# MCXN947_cm33_core0 register map
Vendor: nxp.com; File version: 1.0
CPU: CM33 r2p0, little endian, MPU, FPU, VTOR, 3 interrupt priority bits
Registers are 32-bit, read-write, reset 0x0 unless marked. A register's access mark holds for its fields unless they carry their own. Offsets are from the block's base; [hi:lo] are bit positions; lines under a group give offsets from that group; {n}, {i} and the like mark numbered series; 'fields as' and 'values as' point back to an identical list.

## ITRC0 — Intrusion and Tamper Response Controller
Base 0x40026000
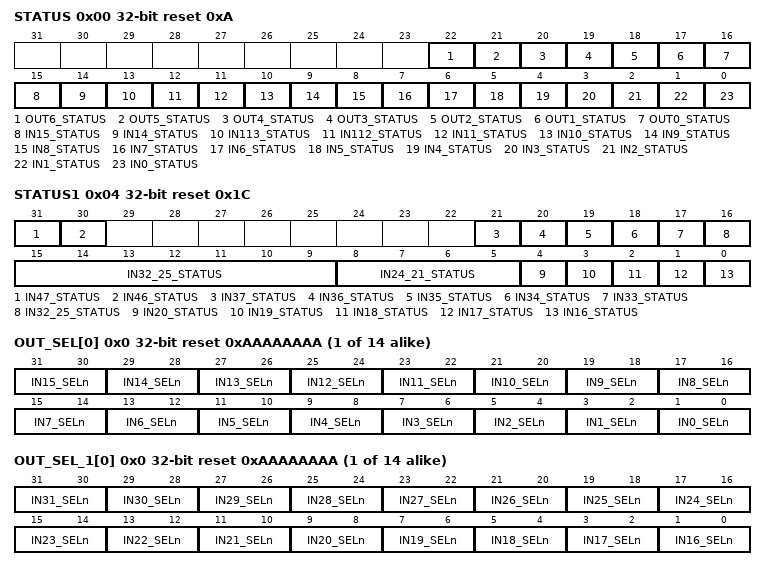
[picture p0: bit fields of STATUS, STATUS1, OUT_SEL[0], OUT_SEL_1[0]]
0x00 STATUS reset 0xA write-1-clears — ITRC outputs and IN0 to IN15 Status
  [all] fields
    0=DISABLE (Output not triggered.); 1=ENABLE (Output has been triggered.)
  [22] OUT6_STATUS write-1-clears — ITRC triggered TMPR_OUT1 internal signal connected to various on-chip multiplexers.
  [21] OUT5_STATUS write-1-clears — ITRC triggered TMPR_OUT0 internal signal connected to various on-chip multiplexers.
  [20] OUT4_STATUS write-1-clears — ITRC triggered CHIP_RESET to reset the chip after all other response process finished.
  [19] OUT3_STATUS write-1-clears — ITRC triggered RAM_ZEROIZE.
  [18] OUT2_STATUS write-1-clears — ITRC triggered PUF_ZEROIZE to clear PUF key store and RAM.
  [17] OUT1_STATUS write-1-clears — ITRC triggered ELS_RESET to clear ELS key store.
  [16] OUT0_STATUS write-1-clears — ITRC triggered ITRC_IRQ output.
  [15] IN15_STATUS write-1-clears — Software event 1 occurred.
  [14] IN14_STATUS write-1-clears — Software event 0 occurred.
  [13] IN113_STATUS write-1-clears — FREQME out of range status output.
  [12] IN112_STATUS write-1-clears — Watchdog 1 timer event interrupt.
  [11] IN11_STATUS write-1-clears — Code Watchdog 1 interrupt.
  [10] IN10_STATUS write-1-clears — PKC module detected an error event.
  [9] IN9_STATUS write-1-clears — SPC VDD_CORE glitch detect event occurred.
  [8] IN8_STATUS write-1-clears — ELS error event occurred.
  [7] IN7_STATUS write-1-clears — AHB secure bus checkers detected illegal access.
  [6] IN6_STATUS write-1-clears — Flash ECC mismatch event occurred.
  [5] IN5_STATUS write-1-clears — Watch Dog timer event occurred.
  [4] IN4_STATUS write-1-clears — SPC VDD_CORE_LVD detect.
  [3] IN3_STATUS write-1-clears — VDD_MAIN volt tamper output.
  [2] IN2_STATUS write-1-clears — Code Watchdog 0 interrupt.
  [1] IN1_STATUS write-1-clears — TDET tamper output.
  [0] IN0_STATUS write-1-clears — GDET0 & 1 interrupt.
0x04 STATUS1 reset 0x1C write-1-clears — ITRC IN16 to IN47 Status
  [all] fields
    values as the fields of STATUS
  [31] IN47_STATUS write-1-clears — TRNG HW error event occurred.
  [30] IN46_STATUS write-1-clears — SM3 SGI error event occurred.
  [21] IN37_STATUS write-1-clears — FLEXSPI GCM error event occurred.
  [20] IN36_STATUS write-1-clears — SPC VDD_IO high voltage detect event occurred.
  [19] IN35_STATUS write-1-clears — SPC VDD_SYS_HVD high voltage detect event occurred.
  [18] IN34_STATUS write-1-clears — SPC VDD_CORE high voltage detect event occurred.
  [17] IN33_STATUS write-1-clears — GDET0/1 SFR error event occurred.
  [16:9] IN32_25_STATUS write-1-clears — MSF SOCTRIM 7~0 ECC error event occurred.
  [8:5] IN24_21_STATUS write-1-clears — INTM interrupt monitor error 3~0 event occurred.
  [4] IN20_STATUS write-1-clears — VDD_MAIN clock tamper output event occurred.
  [3] IN19_STATUS write-1-clears — Reserved
  [2] IN18_STATUS write-1-clears — Reserved
  [1] IN17_STATUS write-1-clears — SPC VDD_IO_LVD detect event occurred.
  [0] IN16_STATUS write-1-clears — SSPC VDD_SYS_LVD detect event occurred.
{0x8+8i} OUTx_SEL[{i}] (i=0..6) group
  {0x0+4j} OUT_SEL[{j}] (j=0..1) reset 0xAAAAAAAA — Trigger Source IN0 to IN15 selector
    [31:30] IN15_SELn — Selects software event 1 as a trigger source.
    [29:28] IN14_SELn — Selects software event 0 as a trigger source.
    [27:26] IN13_SELn — Selects FREQME out of range status output as a trigger source.
    [25:24] IN12_SELn — Selects Watchdog 1 timer event as a trigger source.
    [23:22] IN11_SELn — Selects Code Watchdog 1 event as a trigger source.
    [21:20] IN10_SELn — Selects PKC error event as a trigger source.
    [19:18] IN9_SELn — Selects SPC VDD_CORE glitch detector as a trigger source.
    [17:16] IN8_SELn — Selects ELS error event as a trigger source.
    [15:14] IN7_SELn — Selects AHB secure bus or MBC bus illegal access event as a trigger source.
    [13:12] IN6_SELn — Selects Flash ECC mismatch event as a trigger source.
    [11:10] IN5_SELn — Selects Watchdog 0 timer event as a trigger source.
    [9:8] IN4_SELn — Selects low-voltage event on VDD_CORE rail as a trigger source.
    [7:6] IN3_SELn — Selects VDD_MAIN voltage tamper event as a trigger source.
    [5:4] IN2_SELn — Selects Code Watchdog 0 event as a trigger source.
    [3:2] IN1_SELn — Selects TDET event as a trigger source.
    [1:0] IN0_SELn — Selects digital glitch detector as a trigger source.
{0x48+8i} OUTx_SEL_1[{i}] (i=0..6) group
  {0x0+4j} OUT_SEL_1[{j}] (j=0..1) reset 0xAAAAAAAA — Trigger Source IN16 to IN31 selector
    [2n-31:2n-32] IN{n}_SELn (n=25..31) — Selects MSF SOCTRIM {n-25} ECC error event as a trigger source.
    [2n-31:2n-32] IN{n}_SELn (n=21..24) — Selects INTM interrupt monitor error {n-21} event as a trigger source.
    [9:8] IN20_SELn — Selects VDD_MAIN clock tamper output event as a trigger source.
    [7:6] IN19_SELn — Selects VDD_MAIN temperature tamper output event as a trigger source.
    [5:4] IN18_SELn — Reserved.
    [3:2] IN17_SELn — Selects SPC VDD_IO_LVD detect as a trigger source.
    [1:0] IN16_SELn — Selects SPC VDD_SYS_LVD detect as a trigger source.
{0x88+8i} OUTx_SEL_2[{i}] (i=0..6) group
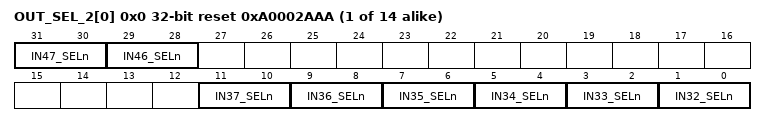
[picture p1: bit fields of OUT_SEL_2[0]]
  {0x0+4j} OUT_SEL_2[{j}] (j=0..1) reset 0xA0002AAA — Trigger source IN32 to IN47 selector
    [31:30] IN47_SELn — Selects TRNG HW Error as a trigger source.
    [29:28] IN46_SELn — Selects SM3 SGI error as a trigger source.
    [11:10] IN37_SELn — Selects FLEXSPI GCM error as a trigger source.
    [9:8] IN36_SELn — Selects VDD_IO_HVD as a trigger source.
    [7:6] IN35_SELn — Selects VDD_SYS_HVD as a trigger source.
    [5:4] IN34_SELn — Selects SPC VDD_CORE_HVD as a trigger source.
    [3:2] IN33_SELn — Selects GDET0 & 1 SFR error detect as a trigger source.
    [1:0] IN32_SELn — Selects MSF SOCTRIM 7 ECC error event as a trigger source.
0xF0 SW_EVENT0 wo — Software event 0
  [31:0] TRIGGER_SW_EVENT_0 — Trigger software event 0.
0xF4 SW_EVENT1 wo — Software event 1
  [31:0] TRIGGER_SW_EVENT_1 — Trigger software event 1.
